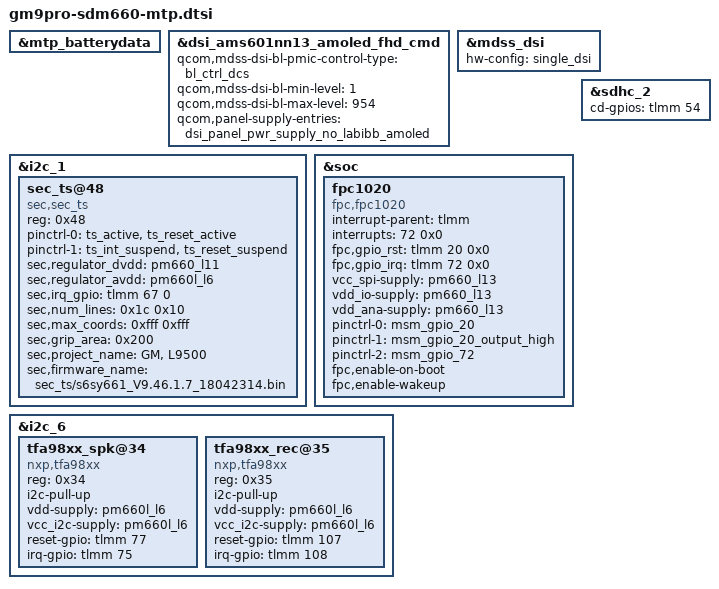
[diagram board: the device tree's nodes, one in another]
 /* SPDX-License-Identifier: GPL-2.0 */

#include "gm9pro-sdm660-camera-sensor-mtp.dtsi"

&mtp_batterydata {
	/delete-node/ qcom,itech_3000mah;
	/delete-node/ qcom,ascent_3450mah;

	#include "fg-gen3-batterydata-l9500atl_3800mah.dtsi"
};

&dsi_ams601nn13_amoled_fhd_cmd {
	qcom,mdss-dsi-bl-pmic-control-type = "bl_ctrl_dcs";
	qcom,mdss-dsi-bl-min-level = <1>;
	qcom,mdss-dsi-bl-max-level = <954>;
	qcom,panel-supply-entries = <&dsi_panel_pwr_supply_no_labibb_amoled>;
};

&mdss_dsi {
	hw-config = "single_dsi";
};

&i2c_1 {
	status = "okay";

	sec_ts@48 {
		compatible = "sec,sec_ts";
		reg = <0x48>;
		pinctrl-names = "pmx_ts_active", "pmx_ts_suspend";
		pinctrl-0 = <&ts_active &ts_reset_active>;
		pinctrl-1 = <&ts_int_suspend &ts_reset_suspend>;
		sec,regulator_dvdd = "pm660_l11";
		sec,regulator_avdd = "pm660l_l6";
		sec,irq_gpio = <&tlmm 67 0>;
		sec,num_lines = <0x1c 0x10>;
		sec,max_coords = <0xfff 0xfff>;
		sec,grip_area = <0x200>;
		sec,project_name = "GM", "L9500";
		sec,firmware_name = "sec_ts/s6sy661_V9.46.1.7_18042314.bin";
	};
};

&soc {
	fpc1020 {
		status = "okay";
		compatible = "fpc,fpc1020";
		interrupt-parent = <&tlmm>;
		interrupts = <72 0x0>;
		fpc,gpio_rst    = <&tlmm 20 0x0>;
		fpc,gpio_irq    = <&tlmm 72 0x0>;
		vcc_spi-supply  = <&pm660_l13>;
		vdd_io-supply   = <&pm660_l13>;
		vdd_ana-supply  = <&pm660_l13>;
		pinctrl-names = "fpc1020_reset_reset",
			"fpc1020_reset_active",
			"fpc1020_irq_active";
		pinctrl-0 = <&msm_gpio_20>;
		pinctrl-1 = <&msm_gpio_20_output_high>;
		pinctrl-2 = <&msm_gpio_72>;
		fpc,enable-on-boot;
		fpc,enable-wakeup;
	};
};

&i2c_6 {
	tfa98xx_spk@34 {
		status = "okay";
		compatible = "nxp,tfa98xx";
		reg = <0x34>;
		i2c-pull-up;
		vdd-supply = <&pm660l_l6>;
		vcc_i2c-supply = <&pm660l_l6>;
		reset-gpio = <&tlmm 77 0>;
		irq-gpio = <&tlmm 75 0>;
	};

	tfa98xx_rec@35 {
		status = "okay";
		compatible = "nxp,tfa98xx";
		reg = <0x35>;
		i2c-pull-up;
		vdd-supply = <&pm660l_l6>;
		vcc_i2c-supply = <&pm660l_l6>;
		reset-gpio = <&tlmm 107 0>;
		irq-gpio = <&tlmm 108 0>;
	};
};

&sdhc_2 {
	cd-gpios = <&tlmm 54 0x0>;
};
